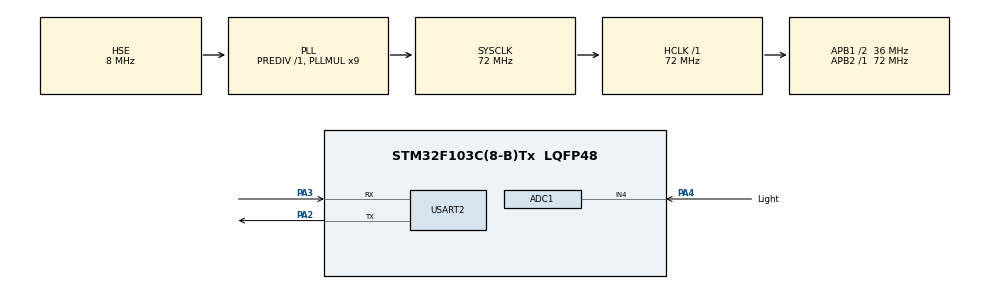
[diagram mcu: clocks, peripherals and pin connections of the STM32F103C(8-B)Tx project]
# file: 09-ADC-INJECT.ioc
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ADC1.Channel-0\#ChannelRegularConversion=ADC_CHANNEL_4
ADC1.Channel-1\#ChannelInjectedConversion=ADC_CHANNEL_TEMPSENSOR
ADC1.EnableInjectedConversion=ENABLE
ADC1.InjNumberOfConversion=1
ADC1.InjectedOffset-1\#ChannelInjectedConversion=0
ADC1.InjectedRank-1\#ChannelInjectedConversion=1
ADC1.NbrOfConversionFlag=1
ADC1.Rank-0\#ChannelRegularConversion=1
ADC1.SamplingTime-0\#ChannelRegularConversion=ADC_SAMPLETIME_1CYCLE_5
ADC1.SamplingTime-1\#ChannelInjectedConversion=ADC_SAMPLETIME_239CYCLES_5
ADC1.master=1
Mcu.Family=STM32F1
Mcu.Name=STM32F103C(8-B)Tx
Mcu.Package=LQFP48
NVIC.ADC1_2_IRQn=true\:0\:0\:false\:false\:true\:true\:true\:true
NVIC.PriorityGroup=NVIC_PRIORITYGROUP_4
PA13.Mode=Serial_Wire
PA13.Signal=SYS_JTMS-SWDIO
PA14.Mode=Serial_Wire
PA14.Signal=SYS_JTCK-SWCLK
PA2.Mode=Asynchronous
PA2.Signal=USART2_TX
PA3.Mode=Asynchronous
PA3.Signal=USART2_RX
PA4.GPIO_Label=Light
PA4.Signal=ADCx_IN4
PC14-OSC32_IN.Mode=LSE-External-Oscillator
PC14-OSC32_IN.Signal=RCC_OSC32_IN
PC15-OSC32_OUT.Mode=LSE-External-Oscillator
PC15-OSC32_OUT.Signal=RCC_OSC32_OUT
PD0-OSC_IN.Mode=HSE-External-Oscillator
PD0-OSC_IN.Signal=RCC_OSC_IN
PD1-OSC_OUT.Mode=HSE-External-Oscillator
PD1-OSC_OUT.Signal=RCC_OSC_OUT
ProjectManager.HeapSize=0x200
ProjectManager.StackSize=0x400
ProjectManager.TargetToolchain=MDK-ARM V5.32
RCC.ADCPresc=RCC_ADCPCLK2_DIV6
RCC.AHBFreq_Value=72000000
RCC.APB1CLKDivider=RCC_HCLK_DIV2
RCC.APB1Freq_Value=36000000
RCC.APB1TimFreq_Value=72000000
RCC.APB2Freq_Value=72000000
RCC.APB2TimFreq_Value=72000000
RCC.HCLKFreq_Value=72000000
RCC.PLLMUL=RCC_PLL_MUL9
RCC.PLLSourceVirtual=RCC_PLLSOURCE_HSE
RCC.SYSCLKFreq_VALUE=72000000
RCC.SYSCLKSource=RCC_SYSCLKSOURCE_PLLCLK
RCC.USBFreq_Value=72000000
SH.ADCx_IN4.0=ADC1_IN4,IN4
USART2.VirtualMode=VM_ASYNC
VP_ADC1_TempSens_Input.Mode=IN-TempSens
board=custom

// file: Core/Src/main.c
/* USER CODE BEGIN Header */
/**
  ******************************************************************************
  * @file           : main.c
  * @brief          : Main program body
  ******************************************************************************
  * @attention
  *
  * Copyright (c) 2026 STMicroelectronics.
  * All rights reserved.
  *
  * This software is licensed under terms that can be found in the LICENSE file
  * in the root directory of this software component.
  * If no LICENSE file comes with this software, it is provided AS-IS.
  *
  ******************************************************************************
  */
/* USER CODE END Header */
#include "main.h"
#include "adc.h"
#include "usart.h"
#include "gpio.h"

/* USER CODE BEGIN Includes */
#include <stdio.h>
/* USER CODE END Includes */

/* USER CODE BEGIN PV */
uint32_t adc_val[2];      /* [0] = 规则组光敏   [1] = 注入组内部温度 */
float voltage[1];         /* 光敏电压 */
float temp;               /* 芯片温度 */
/* USER CODE END PV */

void SystemClock_Config(void);

int main(void)
{

  /* MCU Configuration--------------------------------------------------------*/

  /* Reset of all peripherals, Initializes the Flash interface and the Systick. */
  HAL_Init();

  /* Configure the system clock */
  SystemClock_Config();

  /* Initialize all configured peripherals */
  MX_GPIO_Init();
  MX_ADC1_Init();
  MX_USART2_UART_Init();
  /* USER CODE BEGIN 2 */
  HAL_ADCEx_Calibration_Start(&hadc1);              /* 上电校准，F1 必做 */
  /* USER CODE END 2 */

  /* Infinite loop */
  /* USER CODE BEGIN WHILE */
  while (1)
  {
    HAL_ADC_Start_IT(&hadc1);            /* 规则组：中断方式启动，完成进 ConvCpltCallback */
    HAL_ADCEx_InjectedStart_IT(&hadc1);  /* ★ 注入组：单独启动，完成进 InjectedConvCpltCallback */

    HAL_Delay(500);                      /* 等两次转换的中断都收完 */

    voltage[0] = (float)adc_val[0] / 4095 * 3.3f;      /* 光敏：原始值 → 电压 */
    float vsense = (float)adc_val[1] * 3.3f / 4095.0f; /* 温度：原始值 → 电压 */
    temp = (1.43f - vsense) / 0.0043f + 25.0f;         /* 电压 → 温度（V25=1.43V，斜率 4.3mV/℃） */

    printf("Light:%.3fv adc:%d\r\n", (float)voltage[0], (int)adc_val[0]);
    printf("T:%d -> %.3fv -> %.1fC\r\n", (int)adc_val[1], vsense, temp);
    /* USER CODE END WHILE */

  }
}

void SystemClock_Config(void)
{
  RCC_OscInitTypeDef RCC_OscInitStruct = {0};
  RCC_ClkInitTypeDef RCC_ClkInitStruct = {0};
  RCC_PeriphCLKInitTypeDef PeriphClkInit = {0};

  /** Initializes the RCC Oscillators according to the specified parameters
  * in the RCC_OscInitTypeDef structure.
  */
  RCC_OscInitStruct.OscillatorType = RCC_OSCILLATORTYPE_HSE;
  RCC_OscInitStruct.HSEState = RCC_HSE_ON;
  RCC_OscInitStruct.HSEPredivValue = RCC_HSE_PREDIV_DIV1;
  RCC_OscInitStruct.HSIState = RCC_HSI_ON;
  RCC_OscInitStruct.PLL.PLLState = RCC_PLL_ON;
  RCC_OscInitStruct.PLL.PLLSource = RCC_PLLSOURCE_HSE;
  RCC_OscInitStruct.PLL.PLLMUL = RCC_PLL_MUL9;
  if (HAL_RCC_OscConfig(&RCC_OscInitStruct) != HAL_OK)
  {
    Error_Handler();
  }

  /** Initializes the CPU, AHB and APB buses clocks
  */
  RCC_ClkInitStruct.ClockType = RCC_CLOCKTYPE_HCLK|RCC_CLOCKTYPE_SYSCLK
                              |RCC_CLOCKTYPE_PCLK1|RCC_CLOCKTYPE_PCLK2;
  RCC_ClkInitStruct.SYSCLKSource = RCC_SYSCLKSOURCE_PLLCLK;
  RCC_ClkInitStruct.AHBCLKDivider = RCC_SYSCLK_DIV1;
  RCC_ClkInitStruct.APB1CLKDivider = RCC_HCLK_DIV2;
  RCC_ClkInitStruct.APB2CLKDivider = RCC_HCLK_DIV1;

  if (HAL_RCC_ClockConfig(&RCC_ClkInitStruct, FLASH_LATENCY_2) != HAL_OK)
  {
    Error_Handler();
  }
  PeriphClkInit.PeriphClockSelection = RCC_PERIPHCLK_ADC;
  PeriphClkInit.AdcClockSelection = RCC_ADCPCLK2_DIV6;
  if (HAL_RCCEx_PeriphCLKConfig(&PeriphClkInit) != HAL_OK)
  {
    Error_Handler();
  }
}

/* USER CODE BEGIN 4 */
/* 规则组转换完成回调（HAL __weak 函数，名字不能改） */
void HAL_ADC_ConvCpltCallback(ADC_HandleTypeDef* hadc)
{
  if (hadc->Instance == ADC1)               /* 判断是哪个 ADC 触发 */
  {
    adc_val[0] = HAL_ADC_GetValue(hadc);    /* 规则组所有通道共用一个 DR */
  }
}

/* 注入组转换完成回调 —— 和上面是两个独立回调 */
void HAL_ADCEx_InjectedConvCpltCallback(ADC_HandleTypeDef* hadc)
{
  if (hadc->Instance == ADC1)
  {
    /* ★ 注入组要用专用函数读 JDR1~JDR4，不能用 HAL_ADC_GetValue */
    adc_val[1] = HAL_ADCEx_InjectedGetValue(hadc, ADC_INJECTED_RANK_1);
  }
}

/* printf 重定向（Keil 需勾 Use MicroLIB） */
int fputc(int ch, FILE *f)
{
  HAL_UART_Transmit(&huart2, (uint8_t *)&ch, 1, HAL_MAX_DELAY);
  return ch;
}
/* USER CODE END 4 */

void Error_Handler(void)
{
  __disable_irq();
  while (1)
  {
  }
}
